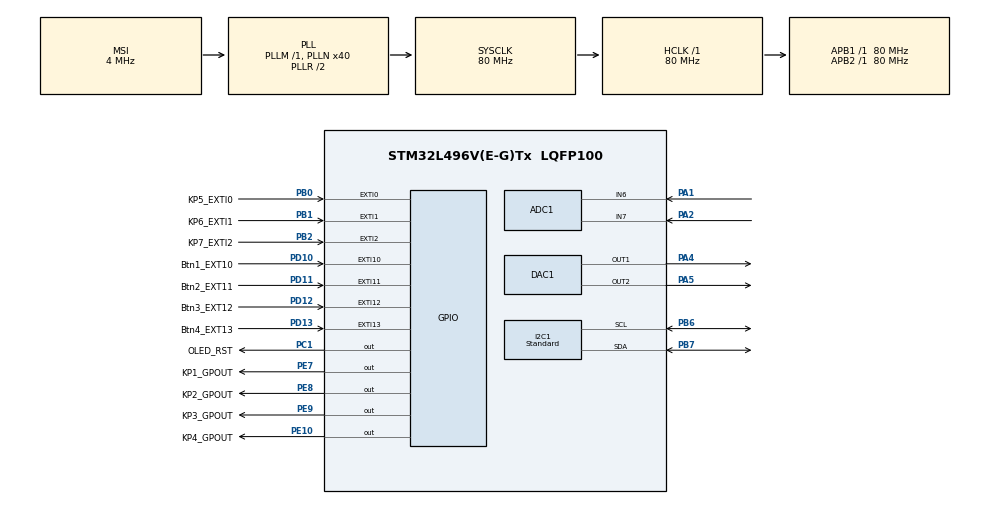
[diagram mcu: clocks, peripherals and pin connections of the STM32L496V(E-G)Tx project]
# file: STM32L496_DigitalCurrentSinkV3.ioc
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ADC1.Channel-0\#ChannelRegularConversion=ADC_CHANNEL_6
ADC1.Channel-1\#ChannelRegularConversion=ADC_CHANNEL_7
ADC1.ContinuousConvMode=ENABLE
ADC1.DMAContinuousRequests=ENABLE
ADC1.NbrOfConversion=2
ADC1.NbrOfConversionFlag=1
ADC1.OffsetNumber-0\#ChannelRegularConversion=ADC_OFFSET_NONE
ADC1.OffsetNumber-1\#ChannelRegularConversion=ADC_OFFSET_NONE
ADC1.OversamplingMode=ENABLE
ADC1.Rank-0\#ChannelRegularConversion=1
ADC1.Rank-1\#ChannelRegularConversion=2
ADC1.Ratio=ADC_OVERSAMPLING_RATIO_32
ADC1.RightBitShift=ADC_RIGHTBITSHIFT_8
ADC1.SamplingTime-0\#ChannelRegularConversion=ADC_SAMPLETIME_2CYCLES_5
ADC1.SamplingTime-1\#ChannelRegularConversion=ADC_SAMPLETIME_2CYCLES_5
ADC1.master=1
DAC1.DAC_Channel-DAC_OUT2=DAC_CHANNEL_2
DAC1.DAC_OutputBuffer-DAC_OUT1=DAC_OUTPUTBUFFER_DISABLE
DAC1.DAC_OutputBuffer-DAC_OUT2=DAC_OUTPUTBUFFER_DISABLE
DAC1.DAC_Trigger-DAC_OUT1=DAC_TRIGGER_T6_TRGO
DAC1.DAC_Trigger-DAC_OUT2=DAC_TRIGGER_T7_TRGO
DAC1.WaveGeneration-DAC_OUT1=DISABLE
DAC1.WaveGeneration-DAC_OUT2=DISABLE
Dma.ADC1.0.Direction=DMA_PERIPH_TO_MEMORY
Dma.ADC1.0.Instance=DMA1_Channel1
Dma.ADC1.0.MemDataAlignment=DMA_MDATAALIGN_WORD
Dma.ADC1.0.MemInc=DMA_MINC_ENABLE
Dma.ADC1.0.Mode=DMA_CIRCULAR
Dma.ADC1.0.PeriphDataAlignment=DMA_PDATAALIGN_WORD
Dma.ADC1.0.PeriphInc=DMA_PINC_DISABLE
Dma.ADC1.0.Priority=DMA_PRIORITY_LOW
Dma.Request0=ADC1
I2C1.Analog_Filter=I2C_ANALOGFILTER_ENABLE
I2C1.I2C_Fall_Time=0
I2C1.I2C_Rise_Time=0
I2C1.I2C_Speed_Mode=I2C_Standard
I2C1.NoStretchMode=I2C_NOSTRETCH_DISABLE
I2C1.Speed=100
Mcu.Family=STM32L4
Mcu.Name=STM32L496V(E-G)Tx
Mcu.Package=LQFP100
NVIC.ADC1_2_IRQn=true\:0\:0\:false\:false\:true\:true\:true
NVIC.DMA1_Channel1_IRQn=true\:0\:0\:false\:false\:true\:false\:true
NVIC.EXTI0_IRQn=true\:0\:0\:false\:false\:true\:true\:true
NVIC.EXTI15_10_IRQn=true\:0\:0\:false\:false\:true\:true\:true
NVIC.EXTI1_IRQn=true\:0\:0\:false\:false\:true\:true\:true
NVIC.EXTI2_IRQn=true\:0\:0\:false\:false\:true\:true\:true
NVIC.PriorityGroup=NVIC_PRIORITYGROUP_4
NVIC.TIM1_BRK_TIM15_IRQn=true\:0\:0\:false\:false\:true\:true\:true
NVIC.TIM1_TRG_COM_TIM17_IRQn=true\:0\:0\:false\:false\:true\:true\:true
NVIC.TIM1_UP_TIM16_IRQn=true\:0\:0\:false\:false\:true\:true\:true
NVIC.TIM5_IRQn=true\:0\:0\:false\:false\:true\:true\:true
NVIC.TIM6_DAC_IRQn=true\:0\:0\:false\:false\:true\:true\:true
NVIC.TIM7_IRQn=true\:0\:0\:false\:false\:true\:true\:true
PA1.Signal=ADCx_IN6
PA13\ (JTMS/SWDIO).Mode=Trace_Asynchronous_SW
PA13\ (JTMS/SWDIO).Signal=SYS_JTMS-SWDIO
PA14\ (JTCK/SWCLK).Mode=Trace_Asynchronous_SW
PA14\ (JTCK/SWCLK).Signal=SYS_JTCK-SWCLK
PA2.Signal=ADCx_IN7
PA4.Signal=COMP_DAC11_group
PA5.Signal=COMP_DAC12_group
PB0.GPIO_Label=KP5_EXTI0
PB0.GPIO_PuPd=GPIO_PULLDOWN
PB0.Signal=GPXTI0
PB1.GPIO_Label=KP6_EXTI1
PB1.GPIO_PuPd=GPIO_PULLDOWN
PB1.Signal=GPXTI1
PB2.GPIO_Label=KP7_EXTI2
PB2.GPIO_PuPd=GPIO_PULLDOWN
PB2.Signal=GPXTI2
PB3\ (JTDO/TRACESWO).Mode=Trace_Asynchronous_SW
PB3\ (JTDO/TRACESWO).Signal=SYS_JTDO-SWO
PB6.GPIO_FM6=__NULL
PB6.GPIO_PuPdOD=GPIO_PULLUP
PB6.GPIO_Speed=GPIO_SPEED_FREQ_LOW
PB6.Mode=I2C
PB6.Signal=I2C1_SCL
PB7.GPIO_FM7=__NULL
PB7.GPIO_PuPdOD=GPIO_PULLUP
PB7.GPIO_Speed=GPIO_SPEED_FREQ_LOW
PB7.Mode=I2C
PB7.Signal=I2C1_SDA
PC1.GPIO_Label=OLED_RST
PC1.GPIO_PuPd=GPIO_PULLUP
PC1.GPIO_Speed=GPIO_SPEED_FREQ_HIGH
PC1.PinState=GPIO_PIN_SET
PC1.Signal=GPIO_Output
PD10.GPIO_Label=Btn1_EXT10
PD10.GPIO_ModeDefaultEXTI=GPIO_MODE_IT_FALLING
PD10.GPIO_PuPd=GPIO_PULLUP
PD10.Signal=GPXTI10
PD11.GPIO_Label=Btn2_EXT11
PD11.GPIO_ModeDefaultEXTI=GPIO_MODE_IT_FALLING
PD11.GPIO_PuPd=GPIO_PULLUP
PD11.Signal=GPXTI11
PD12.GPIO_Label=Btn3_EXT12
PD12.GPIO_ModeDefaultEXTI=GPIO_MODE_IT_FALLING
PD12.GPIO_PuPd=GPIO_PULLUP
PD12.Signal=GPXTI12
PD13.GPIO_Label=Btn4_EXT13
PD13.GPIO_ModeDefaultEXTI=GPIO_MODE_IT_FALLING
PD13.GPIO_PuPd=GPIO_PULLUP
PD13.Signal=GPXTI13
PE10.GPIO_Label=KP4_GPOUT
PE10.GPIO_PuPd=GPIO_PULLUP
PE10.PinState=GPIO_PIN_SET
PE10.Signal=GPIO_Output
PE7.GPIO_Label=KP1_GPOUT
PE7.GPIO_PuPd=GPIO_PULLUP
PE7.PinState=GPIO_PIN_SET
PE7.Signal=GPIO_Output
PE8.GPIO_Label=KP2_GPOUT
PE8.GPIO_PuPd=GPIO_PULLUP
PE8.PinState=GPIO_PIN_SET
PE8.Signal=GPIO_Output
PE9.GPIO_Label=KP3_GPOUT
PE9.GPIO_PuPd=GPIO_PULLUP
PE9.PinState=GPIO_PIN_SET
PE9.Signal=GPIO_Output
ProjectManager.HeapSize=0x200
ProjectManager.StackSize=0x400
ProjectManager.TargetToolchain=TrueSTUDIO
RCC.ADCCLockSelection=RCC_ADCCLKSOURCE_SYSCLK
RCC.ADCFreq_Value=80000000
RCC.AHBFreq_Value=80000000
RCC.APB1Freq_Value=80000000
RCC.APB1TimFreq_Value=80000000
RCC.APB2Freq_Value=80000000
RCC.APB2TimFreq_Value=80000000
RCC.CortexFreq_Value=80000000
RCC.HCLKFreq_Value=80000000
RCC.HSE_VALUE=8000000
RCC.HSI48_VALUE=48000000
RCC.HSI_VALUE=16000000
RCC.LSE_VALUE=32768
RCC.MSI_VALUE=4000000
RCC.PLLN=40
RCC.PLLSAI1N=16
RCC.SYSCLKFreq_VALUE=80000000
RCC.SYSCLKSource=RCC_SYSCLKSOURCE_PLLCLK
RCC.USBFreq_Value=32000000
RCC.VCOOutputFreq_Value=160000000
SH.ADCx_IN6.0=ADC1_IN6,IN6-Single-Ended
SH.ADCx_IN7.0=ADC1_IN7,IN7-Single-Ended
SH.COMP_DAC11_group.0=DAC1_OUT1,DAC_OUT1
SH.COMP_DAC12_group.0=DAC1_OUT2,DAC_OUT2
TIM15.Period=20000
TIM15.Prescaler=4095
TIM16.Period=8191
TIM16.Prescaler=4095
TIM17.Period=2047
TIM17.Prescaler=1023
TIM5.Period=65535
TIM5.Prescaler=15
TIM6.AutoReloadPreload=TIM_AUTORELOAD_PRELOAD_ENABLE
TIM6.Period=65535
TIM6.Prescaler=1023
TIM6.TIM_MasterOutputTrigger=TIM_TRGO_UPDATE
TIM7.AutoReloadPreload=TIM_AUTORELOAD_PRELOAD_ENABLE
TIM7.Period=65535
TIM7.Prescaler=1023
TIM7.TIM_MasterOutputTrigger=TIM_TRGO_UPDATE
VP_TIM15_VS_ClockSourceINT.Mode=Internal
VP_TIM16_VS_ClockSourceINT.Mode=Enable_Timer
VP_TIM17_VS_ClockSourceINT.Mode=Enable_Timer
VP_TIM5_VS_ClockSourceINT.Mode=Internal
VP_TIM6_VS_ClockSourceINT.Mode=Enable_Timer
VP_TIM7_VS_ClockSourceINT.Mode=Enable_Timer
board=custom

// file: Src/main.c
/* USER CODE BEGIN Header */
/**
  ******************************************************************************
  * @file           : main.c
  * @brief          : Main program body
  ******************************************************************************
  * @attention
  *
  * <h2><center>&copy; Copyright (c) 2019 STMicroelectronics.
  * All rights reserved.</center></h2>
  *
  * This software component is licensed by ST under BSD 3-Clause license,
  * the "License"; You may not use this file except in compliance with the
  * License. You may obtain a copy of the License at:
  *                        opensource.org/licenses/BSD-3-Clause
  *
  ******************************************************************************
  */
/* USER CODE END Header */

#include "main.h"
#include "adc.h"
#include "dac.h"
#include "dma.h"
#include "i2c.h"
#include "tim.h"
#include "gpio.h"

/* USER CODE BEGIN Includes */
#include "utils.h"
#include "ssd1306.h"
/* USER CODE END Includes */

void SystemClock_Config(void);

int main(void)
{

  /* MCU Configuration--------------------------------------------------------*/

  /* Reset of all peripherals, Initializes the Flash interface and the Systick. */
  HAL_Init();

  /* Configure the system clock */
  SystemClock_Config();

  /* Initialize all configured peripherals */
  MX_GPIO_Init();
  MX_DMA_Init();
  MX_ADC1_Init();
  MX_DAC1_Init();
  MX_I2C1_Init();
  MX_TIM5_Init();
  MX_TIM6_Init();
  MX_TIM7_Init();
  MX_TIM15_Init();
  MX_TIM16_Init();
  MX_TIM17_Init();
  /* USER CODE BEGIN 2 */

  Utils_Init();
  /* USER CODE END 2 */

  /* Infinite loop */
  while (1)
  {

  }
}

void SystemClock_Config(void)
{
  RCC_OscInitTypeDef RCC_OscInitStruct = {0};
  RCC_ClkInitTypeDef RCC_ClkInitStruct = {0};
  RCC_PeriphCLKInitTypeDef PeriphClkInit = {0};

  /** Initializes the CPU, AHB and APB busses clocks
  */
  RCC_OscInitStruct.OscillatorType = RCC_OSCILLATORTYPE_MSI;
  RCC_OscInitStruct.MSIState = RCC_MSI_ON;
  RCC_OscInitStruct.MSICalibrationValue = 0;
  RCC_OscInitStruct.MSIClockRange = RCC_MSIRANGE_6;
  RCC_OscInitStruct.PLL.PLLState = RCC_PLL_ON;
  RCC_OscInitStruct.PLL.PLLSource = RCC_PLLSOURCE_MSI;
  RCC_OscInitStruct.PLL.PLLM = 1;
  RCC_OscInitStruct.PLL.PLLN = 40;
  RCC_OscInitStruct.PLL.PLLP = RCC_PLLP_DIV2;
  RCC_OscInitStruct.PLL.PLLQ = RCC_PLLQ_DIV2;
  RCC_OscInitStruct.PLL.PLLR = RCC_PLLR_DIV2;
  if (HAL_RCC_OscConfig(&RCC_OscInitStruct) != HAL_OK)
  {
    Error_Handler();
  }
  /** Initializes the CPU, AHB and APB busses clocks
  */
  RCC_ClkInitStruct.ClockType = RCC_CLOCKTYPE_HCLK|RCC_CLOCKTYPE_SYSCLK
                              |RCC_CLOCKTYPE_PCLK1|RCC_CLOCKTYPE_PCLK2;
  RCC_ClkInitStruct.SYSCLKSource = RCC_SYSCLKSOURCE_PLLCLK;
  RCC_ClkInitStruct.AHBCLKDivider = RCC_SYSCLK_DIV1;
  RCC_ClkInitStruct.APB1CLKDivider = RCC_HCLK_DIV1;
  RCC_ClkInitStruct.APB2CLKDivider = RCC_HCLK_DIV1;

  if (HAL_RCC_ClockConfig(&RCC_ClkInitStruct, FLASH_LATENCY_4) != HAL_OK)
  {
    Error_Handler();
  }
  PeriphClkInit.PeriphClockSelection = RCC_PERIPHCLK_I2C1|RCC_PERIPHCLK_ADC;
  PeriphClkInit.I2c1ClockSelection = RCC_I2C1CLKSOURCE_PCLK1;
  PeriphClkInit.AdcClockSelection = RCC_ADCCLKSOURCE_SYSCLK;
  if (HAL_RCCEx_PeriphCLKConfig(&PeriphClkInit) != HAL_OK)
  {
    Error_Handler();
  }
  /** Configure the main internal regulator output voltage
  */
  if (HAL_PWREx_ControlVoltageScaling(PWR_REGULATOR_VOLTAGE_SCALE1) != HAL_OK)
  {
    Error_Handler();
  }
}

void Error_Handler(void)
{
}

/************************ (C) COPYRIGHT STMicroelectronics *****END OF FILE****/
